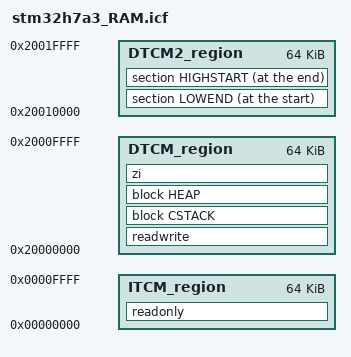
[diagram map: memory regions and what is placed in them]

/*-Memory Regions-*/
define symbol __ICFEDIT_region_ITCM_start__   = 0x00000000;
define symbol __ICFEDIT_region_ITCM_end__     = 0x0000FFFF;
define symbol __ICFEDIT_region_DTCM_start__   = 0x20000000;
define symbol __ICFEDIT_region_DTCM_end__     = 0x2000FFFF;
define symbol __ICFEDIT_region_DTCM2_start__   = 0x20010000;
define symbol __ICFEDIT_region_DTCM2_end__     = 0x2001FFFF;


/*-Sizes-*/
define symbol __ICFEDIT_size_cstack__ = 0x800;
define symbol __ICFEDIT_size_heap__   = 0x400;
/**** End of ICF editor section. ###ICF###*/

define memory mem with size = 4G;
define region ITCM_region      = mem:[from __ICFEDIT_region_ITCM_start__   to __ICFEDIT_region_ITCM_end__];
define region DTCM_region      = mem:[from __ICFEDIT_region_DTCM_start__   to __ICFEDIT_region_DTCM_end__];
define region DTCM2_region      = mem:[from __ICFEDIT_region_DTCM2_start__   to __ICFEDIT_region_DTCM2_end__];

define block CSTACK    with alignment = 8, size = __ICFEDIT_size_cstack__   { };
define block HEAP      with alignment = 8, size = __ICFEDIT_size_heap__     { };

/* initialize by copy { readwrite };*/
do not initialize  { section .noinit };
/*do not initialize { zi };*/

place in ITCM_region   { readonly };
place in DTCM_region   { readwrite,
                        block CSTACK, block HEAP };
place in DTCM_region { zi };

/* Looks like the following definitions determine the location and size of
   the flash loader buffer.
*/
place at start of DTCM2_region {section LOWEND};
place at end of DTCM2_region   {section HIGHSTART};
                        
